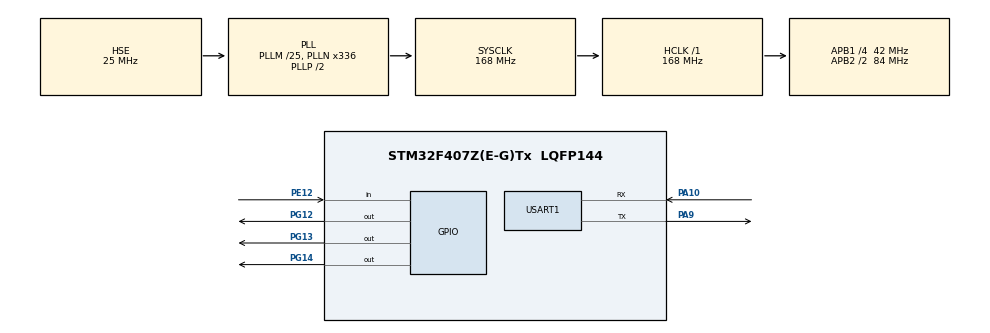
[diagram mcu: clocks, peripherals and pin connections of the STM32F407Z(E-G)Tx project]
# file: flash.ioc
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Mcu.Family=STM32F4
Mcu.Name=STM32F407Z(E-G)Tx
Mcu.Package=LQFP144
NVIC.PriorityGroup=NVIC_PRIORITYGROUP_4
PA10.Mode=Asynchronous
PA10.Signal=USART1_RX
PA9.Mode=Asynchronous
PA9.Signal=USART1_TX
PE12.Signal=GPIO_Input
PG12.Signal=GPIO_Output
PG13.Signal=GPIO_Output
PG14.Signal=GPIO_Output
PH0-OSC_IN.Mode=HSE-External-Oscillator
PH0-OSC_IN.Signal=RCC_OSC_IN
PH1-OSC_OUT.Mode=HSE-External-Oscillator
PH1-OSC_OUT.Signal=RCC_OSC_OUT
ProjectManager.HeapSize=0x200
ProjectManager.StackSize=0x400
ProjectManager.TargetToolchain=EWARM V8.50
RCC.48MHZClocksFreq_Value=84000000
RCC.AHBFreq_Value=168000000
RCC.APB1CLKDivider=RCC_HCLK_DIV4
RCC.APB1Freq_Value=42000000
RCC.APB1TimFreq_Value=84000000
RCC.APB2CLKDivider=RCC_HCLK_DIV2
RCC.APB2Freq_Value=84000000
RCC.APB2TimFreq_Value=168000000
RCC.CortexFreq_Value=168000000
RCC.HCLKFreq_Value=168000000
RCC.HSE_VALUE=25000000
RCC.HSI_VALUE=16000000
RCC.LSE_VALUE=32768
RCC.PLLM=25
RCC.PLLN=336
RCC.PLLSourceVirtual=RCC_PLLSOURCE_HSE
RCC.SYSCLKFreq_VALUE=168000000
RCC.SYSCLKSource=RCC_SYSCLKSOURCE_PLLCLK
RCC.VCOOutputFreq_Value=336000000
USART1.VirtualMode=VM_ASYNC
board=custom

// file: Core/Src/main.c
/* USER CODE BEGIN Header */
/**
  ******************************************************************************
  * @file           : main.c
  * @brief          : Main program body
  ******************************************************************************
  * @attention
  *
  * Copyright (c) 2024 STMicroelectronics.
  * All rights reserved.
  *
  * This software is licensed under terms that can be found in the LICENSE file
  * in the root directory of this software component.
  * If no LICENSE file comes with this software, it is provided AS-IS.
  *
  ******************************************************************************
  */
/* USER CODE END Header */
#include "main.h"
#include <stdio.h>

#define FLASH_USER_START_ADDR   ADDR_FLASH_SECTOR_2   /* Start @ of user Flash area */
#define FLASH_USER_END_ADDR     ADDR_FLASH_SECTOR_11  +  GetSectorSize(FLASH_SECTOR_11) -1 /* End @ of user Flash area : sector start address + sector size -1 */

#define DATA_32                 ((uint32_t)0x12345678)

UART_HandleTypeDef huart1;
static FLASH_EraseInitTypeDef EraseInitStruct;

uint32_t FirstSector = 0, NbOfSectors = 0, Address = 0;
uint32_t SectorError = 0;
__IO uint32_t data32 = 0 , MemoryProgramStatus = 0;

void SystemClock_Config(void);
static void MX_GPIO_Init(void);
static void MX_USART1_UART_Init(void);

static uint32_t GetSectorSize(uint32_t Sector);
static uint32_t GetSector(uint32_t Address);

int fputc(int ch, FILE *f)
{
    /* Place your implementation of fputc here */
    /* e.g. write a character to the EVAL_COM1 and Loop until the end of transmission */
    if( ch == '\n' ){
            ch = '\r';
    HAL_UART_Transmit( &huart1, (uint8_t *)&ch, 1, 0xFFFF );
    ch = '\n';
    }

    HAL_UART_Transmit( &huart1, (uint8_t *)&ch, 1, 0xFFFF );

    return ch;
}

static uint32_t GetSectorSize(uint32_t Sector)
{
  uint32_t sectorsize = 0x00;
  if((Sector == FLASH_SECTOR_0) || (Sector == FLASH_SECTOR_1) || (Sector == FLASH_SECTOR_2) ||\
     (Sector == FLASH_SECTOR_3))
  {
    sectorsize = 16 * 1024;
  }
  else if((Sector == FLASH_SECTOR_4))
  {
    sectorsize = 64 * 1024;
  }
  else
  {
    sectorsize = 128 * 1024;
  }
  return sectorsize;
}

static uint32_t GetSector(uint32_t Address)
{
  uint32_t sector = 0;

  if((Address < ADDR_FLASH_SECTOR_1) && (Address >= ADDR_FLASH_SECTOR_0))
  {
    sector = FLASH_SECTOR_0;
  }
  else if((Address < ADDR_FLASH_SECTOR_2) && (Address >= ADDR_FLASH_SECTOR_1))
  {
    sector = FLASH_SECTOR_1;
  }
  else if((Address < ADDR_FLASH_SECTOR_3) && (Address >= ADDR_FLASH_SECTOR_2))
  {
    sector = FLASH_SECTOR_2;
  }
  else if((Address < ADDR_FLASH_SECTOR_4) && (Address >= ADDR_FLASH_SECTOR_3))
  {
    sector = FLASH_SECTOR_3;
  }
  else if((Address < ADDR_FLASH_SECTOR_5) && (Address >= ADDR_FLASH_SECTOR_4))
  {
    sector = FLASH_SECTOR_4;
  }
  else if((Address < ADDR_FLASH_SECTOR_6) && (Address >= ADDR_FLASH_SECTOR_5))
  {
    sector = FLASH_SECTOR_5;
  }
  else if((Address < ADDR_FLASH_SECTOR_7) && (Address >= ADDR_FLASH_SECTOR_6))
  {
    sector = FLASH_SECTOR_6;
  }
  else if((Address < ADDR_FLASH_SECTOR_8) && (Address >= ADDR_FLASH_SECTOR_7))
  {
    sector = FLASH_SECTOR_7;
  }
  else if((Address < ADDR_FLASH_SECTOR_9) && (Address >= ADDR_FLASH_SECTOR_8))
  {
    sector = FLASH_SECTOR_8;
  }
  else if((Address < ADDR_FLASH_SECTOR_10) && (Address >= ADDR_FLASH_SECTOR_9))
  {
    sector = FLASH_SECTOR_9;
  }
  else if((Address < ADDR_FLASH_SECTOR_11) && (Address >= ADDR_FLASH_SECTOR_10))
  {
    sector = FLASH_SECTOR_10;
  }
  else
  {
    sector = FLASH_SECTOR_11;
  }

  return sector;
}

int main(void)
{
  /* Reset of all peripherals, Initializes the Flash interface and the Systick. */
  HAL_Init();

  SystemClock_Config();

  /* Initialize all configured peripherals */
  MX_GPIO_Init();
  MX_USART1_UART_Init();

  printf("*********************** \r\n\r\n");

// --------- Erase --------------------------------------------------------------------------
 /* Unlock the Flash to enable the flash control register access *************/
  HAL_FLASH_Unlock();

 /* Get the 1st sector to erase */
  FirstSector = GetSector(FLASH_USER_START_ADDR);
 /* Get the number of sector to erase from 1st sector*/
  NbOfSectors = GetSector(FLASH_USER_END_ADDR) - FirstSector + 1;

  /* Fill EraseInit structure*/
  EraseInitStruct.TypeErase = FLASH_TYPEERASE_SECTORS;
  EraseInitStruct.VoltageRange = FLASH_VOLTAGE_RANGE_3;
  EraseInitStruct.Sector = FirstSector;
  EraseInitStruct.NbSectors = NbOfSectors;

  if(HAL_FLASHEx_Erase(&EraseInitStruct, &SectorError) != HAL_OK)
  {
    /*
      Error occurred while sector erase.
      User can add here some code to deal with this error.
      SectorError will contain the faulty sector and then to know the code error on this sector,
      user can call function 'HAL_FLASH_GetError()

      FLASH_ErrorTypeDef errorcode = HAL_FLASH_GetError();      */
    Error_Handler();
  }
// -----------------------------------------------------------------------------------

    /* Note: If an erase operation in Flash memory also concerns data in the data or instruction cache,
     you have to make sure that these data are rewritten before they are accessed during code
     execution. If this cannot be done safely, it is recommended to flush the caches by setting the
     DCRST and ICRST bits in the FLASH_CR register. */
  __HAL_FLASH_DATA_CACHE_DISABLE();
  __HAL_FLASH_INSTRUCTION_CACHE_DISABLE();

  __HAL_FLASH_DATA_CACHE_RESET();
  __HAL_FLASH_INSTRUCTION_CACHE_RESET();

  __HAL_FLASH_INSTRUCTION_CACHE_ENABLE();
  __HAL_FLASH_DATA_CACHE_ENABLE();

 // --------- 32bit write --------------------------------------------------------------------------
    /* Program the user Flash area word by word
    (area defined by FLASH_USER_START_ADDR and FLASH_USER_END_ADDR) ***********/

  Address = FLASH_USER_START_ADDR;

  while (Address < FLASH_USER_END_ADDR)
  {
    if (HAL_FLASH_Program(FLASH_TYPEPROGRAM_WORD, Address, DATA_32) == HAL_OK)
    {
      Address = Address + 4;
    }
    else
    {
      /* Error occurred while writing data in Flash memory.
         User can add here some code to deal with this error

         FLASH_ErrorTypeDef errorcode = HAL_FLASH_GetError(); */
      Error_Handler();
    }
  }
// -----------------------------------------------------------------------------------

    /* Lock the Flash to disable the flash control register access (recommended
     to protect the FLASH memory against possible unwanted operation) *********/
  HAL_FLASH_Lock();

   /* Check if the programmed data is OK
      MemoryProgramStatus = 0: data programmed correctly
      MemoryProgramStatus != 0: number of words not programmed correctly ******/
  Address = FLASH_USER_START_ADDR;
  MemoryProgramStatus = 0x0;

  while (Address < FLASH_USER_END_ADDR)
  {
    data32 = *(__IO uint32_t*)Address;

    if (data32 != DATA_32)
    {
      MemoryProgramStatus++;
    }

    Address = Address + 4;
  }

  /* Check if there is an issue to program data */
  if (MemoryProgramStatus == 0)
  {
    /* No error detected. Switch on LED yellow */
    HAL_GPIO_WritePin(GPIOG, GPIO_PIN_13, GPIO_PIN_RESET);
    printf("**\r\n  Flash memory No error detected. \r\n\r\n");
  }
  else
  {
    /* Error detected. Switch on LED red */
    HAL_GPIO_WritePin(GPIOG, GPIO_PIN_14, GPIO_PIN_RESET);
    Error_Handler();
  }

  while (1)
  {
       printf("** Flash memory Test! ** \r\n\r\n");
       HAL_Delay(1200);

  }// end while
}// end main

void SystemClock_Config(void)
{
  RCC_OscInitTypeDef RCC_OscInitStruct = {0};
  RCC_ClkInitTypeDef RCC_ClkInitStruct = {0};

  /** Configure the main internal regulator output voltage
  */
  __HAL_RCC_PWR_CLK_ENABLE();
  __HAL_PWR_VOLTAGESCALING_CONFIG(PWR_REGULATOR_VOLTAGE_SCALE1);

  /** Initializes the RCC Oscillators according to the specified parameters
  * in the RCC_OscInitTypeDef structure.
  */
  RCC_OscInitStruct.OscillatorType = RCC_OSCILLATORTYPE_HSE;
  RCC_OscInitStruct.HSEState = RCC_HSE_ON;
  RCC_OscInitStruct.PLL.PLLState = RCC_PLL_ON;
  RCC_OscInitStruct.PLL.PLLSource = RCC_PLLSOURCE_HSE;
  RCC_OscInitStruct.PLL.PLLM = 25;
  RCC_OscInitStruct.PLL.PLLN = 336;
  RCC_OscInitStruct.PLL.PLLP = RCC_PLLP_DIV2;
  RCC_OscInitStruct.PLL.PLLQ = 4;
  if (HAL_RCC_OscConfig(&RCC_OscInitStruct) != HAL_OK)
  {
    Error_Handler();
  }

  /** Initializes the CPU, AHB and APB buses clocks
  */
  RCC_ClkInitStruct.ClockType = RCC_CLOCKTYPE_HCLK|RCC_CLOCKTYPE_SYSCLK
                              |RCC_CLOCKTYPE_PCLK1|RCC_CLOCKTYPE_PCLK2;
  RCC_ClkInitStruct.SYSCLKSource = RCC_SYSCLKSOURCE_PLLCLK;
  RCC_ClkInitStruct.AHBCLKDivider = RCC_SYSCLK_DIV1;
  RCC_ClkInitStruct.APB1CLKDivider = RCC_HCLK_DIV4;
  RCC_ClkInitStruct.APB2CLKDivider = RCC_HCLK_DIV2;

  if (HAL_RCC_ClockConfig(&RCC_ClkInitStruct, FLASH_LATENCY_5) != HAL_OK)
  {
    Error_Handler();
  }
}

static void MX_USART1_UART_Init(void)
{

  huart1.Instance = USART1;
  huart1.Init.BaudRate = 921600;
  huart1.Init.WordLength = UART_WORDLENGTH_8B;
  huart1.Init.StopBits = UART_STOPBITS_1;
  huart1.Init.Parity = UART_PARITY_NONE;
  huart1.Init.Mode = UART_MODE_TX_RX;
  huart1.Init.HwFlowCtl = UART_HWCONTROL_NONE;
  huart1.Init.OverSampling = UART_OVERSAMPLING_16;
  if (HAL_UART_Init(&huart1) != HAL_OK)
  {
    Error_Handler();
  }

}

static void MX_GPIO_Init(void)
{
  GPIO_InitTypeDef GPIO_InitStruct = {0};

  /* GPIO Ports Clock Enable */
  __HAL_RCC_GPIOH_CLK_ENABLE();
  __HAL_RCC_GPIOE_CLK_ENABLE();
  __HAL_RCC_GPIOA_CLK_ENABLE();
  __HAL_RCC_GPIOG_CLK_ENABLE();

  /*Configure GPIO pin Output Level */
  HAL_GPIO_WritePin(GPIOG, GPIO_PIN_12|GPIO_PIN_13|GPIO_PIN_14, GPIO_PIN_SET);

  /*Configure GPIO pin : PE12 */
  GPIO_InitStruct.Pin = GPIO_PIN_12;
  GPIO_InitStruct.Mode = GPIO_MODE_INPUT;
  GPIO_InitStruct.Pull = GPIO_NOPULL;
  HAL_GPIO_Init(GPIOE, &GPIO_InitStruct);

  /*Configure GPIO pins : PG12 PG13 PG14 */
  GPIO_InitStruct.Pin = GPIO_PIN_12|GPIO_PIN_13|GPIO_PIN_14;
  GPIO_InitStruct.Mode = GPIO_MODE_OUTPUT_PP;
  GPIO_InitStruct.Pull = GPIO_NOPULL;
  GPIO_InitStruct.Speed = GPIO_SPEED_FREQ_LOW;
  HAL_GPIO_Init(GPIOG, &GPIO_InitStruct);

}

void Error_Handler(void)
{
  /* USER CODE BEGIN Error_Handler_Debug */
  /* User can add his own implementation to report the HAL error return state */
  __disable_irq();
  while (1)
  {
      printf("**\r\n |||||| Flash memory ERROR! |||||| \r\n\r\n");
  }
  /* USER CODE END Error_Handler_Debug */
}
